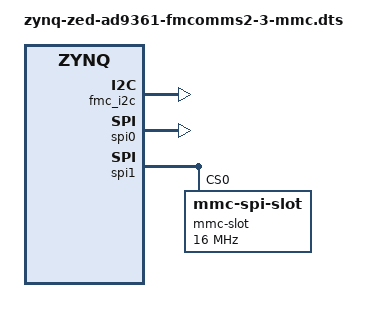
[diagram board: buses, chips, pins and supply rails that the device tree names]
// SPDX-License-Identifier: GPL-2.0
/*
 * Analog Devices AD-FMCOMMS2-EBZ/AD-FMCOMMS3-EBZ
 * https://wiki.analog.com/resources/eval/user-guides/ad-fmcomms2-ebz
 * https://wiki.analog.com/resources/eval/user-guides/ad-fmcomms3-ebz
 *
 * hdl_project: <fmcomms2/zed>
 * board_revision: <>
 *
 * Copyright (C) 2014-2019 Analog Devices Inc.
 */
/dts-v1/;

#include "zynq-zed.dtsi"

/ {
	fpga_axi: fpga-axi@0 {
		compatible = "simple-bus";
		#address-cells = <0x1>;
		#size-cells = <0x1>;
		ranges;

		fmc_i2c: i2c@41620000 {
			compatible = "xlnx,axi-iic-1.01.b", "xlnx,xps-iic-2.00.a";
			reg = <0x41620000 0x10000>;
			interrupt-parent = <&intc>;
			interrupts = <0 55 IRQ_TYPE_LEVEL_HIGH>;
			clocks = <&clkc 15>;
			clock-names = "pclk";

			#size-cells = <0>;
			#address-cells = <1>;
		};

		rx_dma: dma@7c400000 {
			compatible = "adi,axi-dmac-1.00.a";
			reg = <0x7c400000 0x1000>;
			#dma-cells = <1>;
			interrupts = <0 57 IRQ_TYPE_LEVEL_HIGH>;
			clocks = <&clkc 16>;

			adi,channels {
				#size-cells = <0>;
				#address-cells = <1>;

				dma-channel@0 {
					reg = <0>;
					adi,source-bus-width = <64>;
					adi,source-bus-type = <2>;
					adi,destination-bus-width = <64>;
					adi,destination-bus-type = <0>;
				};
			};
		};

		tx_dma: dma@7c420000 {
			compatible = "adi,axi-dmac-1.00.a";
			reg = <0x7c420000 0x1000>;
			#dma-cells = <1>;
			interrupts = <0 56 IRQ_TYPE_LEVEL_HIGH>;
			clocks = <&clkc 16>;

			adi,channels {
				#size-cells = <0>;
				#address-cells = <1>;

				dma-channel@0 {
					reg = <0>;
					adi,source-bus-width = <64>;
					adi,source-bus-type = <0>;
					adi,destination-bus-width = <64>;
					adi,destination-bus-type = <2>;
				};
			};
		};
	};
};

&spi0 {
	status = "okay";
};

&spi1 {
	status = "okay";
	#address-cells = <1>;
	#size-cells = <0>;

	mmc-slot@0 {
		compatible = "mmc-spi-slot";
		reg = <0>;
		status = "okay";
		voltage-ranges = <1800 3600>;
		spi-max-frequency = <16000000>;
		disable-wp;
		disable-cd;
	};
};
